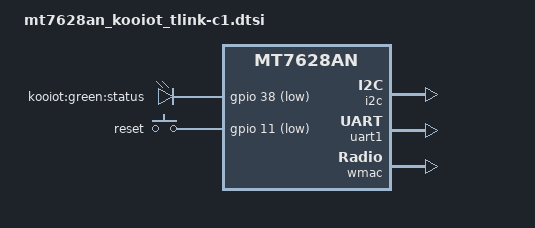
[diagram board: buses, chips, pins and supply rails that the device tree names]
#include "mt7628an.dtsi"

#include <dt-bindings/gpio/gpio.h>
#include <dt-bindings/input/input.h>

/ {
	compatible = "kooiot,tlink-c1", "mediatek,mt7628an-soc";

	aliases {
		led-boot = &led_status;
		led-failsafe = &led_status;
		led-upgrade = &led_status;
	};

	chosen {
		bootargs = "console=ttyS0,57600";
	};

	leds {
		compatible = "gpio-leds";

		/* WLED_AN function is not GPIO. So it will not be mapped to leds
		led_wifi: wifi {
			label = "kooiot:green:wifi";
			gpios = <&gpio 44 GPIO_ACTIVE_LOW>;
		};
		*/

		led_status: status {
			label = "kooiot:green:status";
			gpios = <&gpio 38 GPIO_ACTIVE_LOW>;
			linux,default-trigger = "heartbeat";
		};
	};

	keys {
		compatible = "gpio-keys";

		/*
		wps {
			label = "wps";
			gpios = <&gpio 38 GPIO_ACTIVE_LOW>;
			linux,code = <KEY_WPS_BUTTON>;
		};
		*/

		reset {
			label = "reset";
			gpios = <&gpio 11 GPIO_ACTIVE_LOW>;
			linux,code = <KEY_RESTART>;
		};
	};

	nvmem_sysc: eeprom@10000000 {
		compatible = "ralink,nvmem-mt7688-sysc";
		#address-cells = <1>;
		#size-cells = <0>;

		ralink,nvmem-size = <0x80>;
		ralink,nvmem-writable;
		/* Data cells */
		agpio: agpio@3c {
			reg = <0x3c 0x04>;
		};
		gpio1: gpio1@60 {
			reg = <0x60 0x04>;
		};
		gpio2: gpio2@64 {
			reg = <0x64 0x04>;
		};
	};
};

&state_default {
	gpio {
		groups = "gpio", "wdt";
		function = "gpio";
	};

	wled_an {
		groups = "wled_an";
		function = "wled_an";
	};
};

&i2c {
	status = "okay";
};

&uart1 {
	status = "okay";
};

&ethernet {
	mtd-mac-address = <&factory 0x04>;
};

&wmac {
	status = "okay";
};
